# WKUPAON_CM register map
Vendor: Texas Instruments
Peripheral module from a debugger description file (folder omap5430_ES2_PUBLIC).
Registers are 32-bit, access per field, reset 0x30000 unless marked. A register's access mark holds for its fields unless they carry their own. Offsets are as the file gives them; lines under a group give offsets from that group; [hi:lo] are bit positions; {n}, {i} and the like mark numbered series; 'fields as' and 'values as' point back to an identical list; <NAME> marks a mode.

## WKUPAON_CM
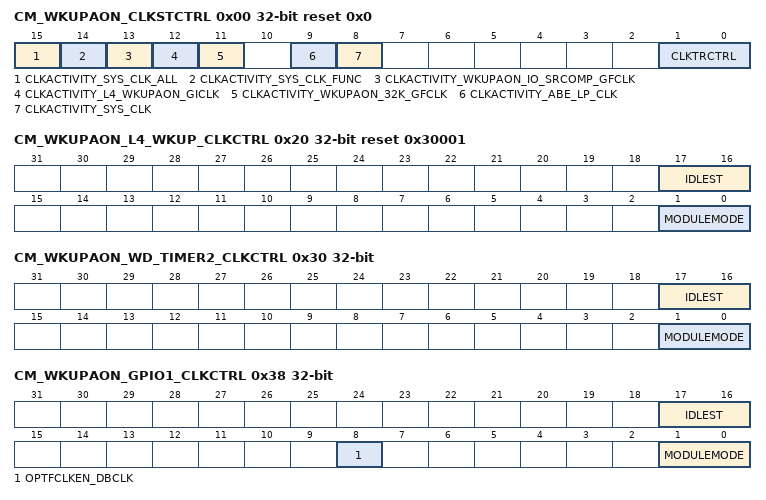
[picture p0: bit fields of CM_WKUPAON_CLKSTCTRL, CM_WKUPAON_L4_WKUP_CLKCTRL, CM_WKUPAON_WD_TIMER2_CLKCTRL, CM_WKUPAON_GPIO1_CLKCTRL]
0x00 CM_WKUPAON_CLKSTCTRL reset 0x0 — This register enables the domain power state transition. It controls the HW supervised domain power state transition between ON-ACTIVE and ON-INACTIVE states. It also holds 1 status bit per clock input of the domain.
  [15] CLKACTIVITY_SYS_CLK_ALL ro — This field indicates the state of the SYS_CLK runing at SCRM level because of any SCRM clock request. [warm reset insensitive]
    0=Corresponding_clock_is_definitely_gated; 1=CLKACTIVITY_SYS_CLK_ALL_1_r (Corresponding clock is running or gating/ungating transition is on-going)
  [14] CLKACTIVITY_SYS_CLK_FUNC ro — This field indicates the state of the functional SYS_CLK clocks in the domain (this exclude activity of EMU_SYS_GCLK clock). [warm reset insensitive]
    0=Corresponding_clock_is_definitely_gated; 1=CLKACTIVITY_SYS_CLK_FUNC_1_r (Corresponding clock is running or gating/ungating transition is on-going)
  [13] CLKACTIVITY_WKUPAON_IO_SRCOMP_GFCLK ro — This field indicates the state of the WKUPAON_IO_SRCOMP_GFCLK clock in the domain. [warm reset insensitive]
    0=Inact (Corresponding clock is definitely gated); 1=Act (Corresponding clock is running or gating/ungating transition is on-going)
  [12] CLKACTIVITY_L4_WKUPAON_GICLK ro — This field indicates the state of the WKUPAON_GICLK clock in the domain. [warm reset insensitive]
    0=Corresponding_clock_is_definitely_gated; 1=CLKACTIVITY_L4_WKUPAON_GICLK_1_r (Corresponding clock is running or gating/ungating transition is on-going)
  [11] CLKACTIVITY_WKUPAON_32K_GFCLK ro — This field indicates the state of the WKUPAON_32K_GFCLK clock in the domain. [warm reset insensitive]
    values as CLKACTIVITY_WKUPAON_IO_SRCOMP_GFCLK
  [9] CLKACTIVITY_ABE_LP_CLK ro — This field indicates the state of the ABE_LP_CLK clock in the domain. [warm reset insensitive]
    values as CLKACTIVITY_WKUPAON_IO_SRCOMP_GFCLK
  [8] CLKACTIVITY_SYS_CLK ro — This field indicates the state of the SYS_CLK clock in the domain (it includes profiling, EMU_SYS_GCLK and all functional SYS_CLK). [warm reset insensitive]
    values as CLKACTIVITY_WKUPAON_IO_SRCOMP_GFCLK
  [1:0] CLKTRCTRL rw — Controls the clock state transition of the WKUPAON clock domain.
    0=NO_SLEEP (NO_SLEEP: Sleep transition cannot be initiated. Wakeup transition may however occur.); 2=SW_WKUP (SW_WKUP: Start a software forced wake-up transition on the domain.); 3=HW_AUTO (HW_AUTO: Automatic transition is enabled. Sleep and wakeup transition are based upon hardware conditions.)
0x20 CM_WKUPAON_L4_WKUP_CLKCTRL ro reset 0x30001 — This register manages the WKUPAON clocks.
  [17:16] IDLEST — Module idle status. [warm reset insensitive]
    0=Func (Module is fully functional, including INTRCONN); 1=Trans (Module is performing transition: wakeup, or sleep, or sleep abortion); 2=Idle (Module is in Idle mode (only INTRCONN part). It is functional if using separate functional clock); 3=Disable (Module is disabled and cannot be accessed)
  [1:0] MODULEMODE — Control the way mandatory clocks are managed.
    1=AUTO (Module is managed automatically by HW according to clock domain transition. A clock domain sleep transition put module into idle. A wakeup domain transition put it back into function. If[1:0] CLKTRCTRL = 0x3 (HW_AUTO), any INTRCONN access to module is always granted. Module clocks may be gated according to the clock domain state.)
0x30 CM_WKUPAON_WD_TIMER2_CLKCTRL — This register manages the WD_TIMER2 clocks.
  [17:16] IDLEST ro — Module idle status. [warm reset insensitive]
    values as CM_WKUPAON_L4_WKUP_CLKCTRL.IDLEST
  [1:0] MODULEMODE rw — Control the way mandatory clocks are managed.
    0=DISABLED (Module is disable by SW. Any INTRCONN access to module results in an error, except if resulting from a module wakeup (asynchronous wakeup).); 2=ENABLE (Module is explicitly enabled. Interface clock (if not used for functions) may be gated according to the clock domain state. Functional clocks are guarantied to stay present. As long as in this configuration, power domain sleep transition cannot happen.)
0x38 CM_WKUPAON_GPIO1_CLKCTRL — This register manages the GPIO1 clocks.
  [17:16] IDLEST ro — Module idle status. [warm reset insensitive]
    values as CM_WKUPAON_L4_WKUP_CLKCTRL.IDLEST
  [8] OPTFCLKEN_DBCLK rw — Optional functional clock control.
    0=FCLK_DIS (Optional functional clock is disabled); 1=FCLK_EN (Optional functional clock is enabled)
  [1:0] MODULEMODE rw — Control the way mandatory clocks are managed.
    0=DISABLED (Module is disable by SW. Any INTRCONN access to module results in an error, except if resulting from a module wakeup (asynchronous wakeup).); 1=RESERVED (Module is managed automatically by HW according to clock domain transition. A clock domain sleep transition put module into idle. A wakeup domain transition put it back into function. If[1:0] CLKTRCTRL = 0x3 (HW_AUTO), any INTRCONN access to module is always granted. Module clocks may be gated according to the clock domain state.)
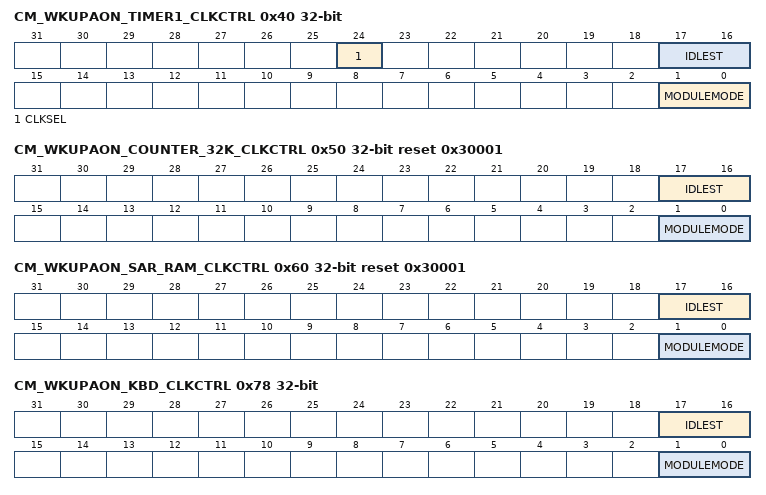
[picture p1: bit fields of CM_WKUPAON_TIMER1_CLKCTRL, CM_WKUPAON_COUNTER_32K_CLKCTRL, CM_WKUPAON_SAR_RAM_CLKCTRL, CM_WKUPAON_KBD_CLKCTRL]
0x40 CM_WKUPAON_TIMER1_CLKCTRL — This register manages the TIMER1 clocks.
  [24] CLKSEL rw — Select the source of the functional clock
    0=SEL_SYS_CLK (Selects the SYS_CLK as the source); 1=SEL_32K_CLK (Selects the 32KHz as the source)
  [17:16] IDLEST ro — Module idle status. [warm reset insensitive]
    values as CM_WKUPAON_L4_WKUP_CLKCTRL.IDLEST
  [1:0] MODULEMODE rw — Control the way mandatory clocks are managed.
    values as CM_WKUPAON_WD_TIMER2_CLKCTRL.MODULEMODE
0x50 CM_WKUPAON_COUNTER_32K_CLKCTRL ro reset 0x30001 — This register manages the COUNTER_32K clocks.
  fields as CM_WKUPAON_L4_WKUP_CLKCTRL
0x60 CM_WKUPAON_SAR_RAM_CLKCTRL ro reset 0x30001 — This register manages the SAR_RAM clocks.
  [17:16] IDLEST — Module idle status. [warm reset insensitive]
    values as CM_WKUPAON_L4_WKUP_CLKCTRL.IDLEST
  [1:0] MODULEMODE — Control the way mandatory clocks are managed.
    1=AUTO (Module is managed automatically by HW according to clock domain transition. A clock domain sleep transition put module into idle. A wakeup domain transition put it back into function. If[1:0]CLKTRCTRL = 0x3 (HW_AUTO), any INTRCONN access to module is always granted. Module clocks may be gated according to the clock domain state.)
0x78 CM_WKUPAON_KBD_CLKCTRL — This register manages the KBD clocks.
  fields as CM_WKUPAON_WD_TIMER2_CLKCTRL
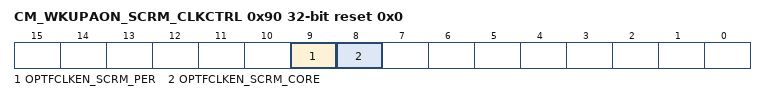
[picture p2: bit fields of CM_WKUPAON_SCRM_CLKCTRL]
0x90 CM_WKUPAON_SCRM_CLKCTRL reset 0x0 — This register manages the SCRM clocks.
  [9] OPTFCLKEN_SCRM_PER rw — Optional functional clock control. 0x0: Optional functional clock is disabled 0x1: Optional functional clock is enabled
  [8] OPTFCLKEN_SCRM_CORE rw — Optional functional clock control.
    values as CM_WKUPAON_GPIO1_CLKCTRL.OPTFCLKEN_DBCLK
0x98 CM_WKUPAON_IO_SRCOMP_CLKCTRL reset 0x0 — This register manages the clock delivered to the IO Slew rate compensation cells. [warm reset insensitive]
  [8] CLKEN_SRCOMP_FCLK rw — Functional clock control.
    0=FCLK_DIS (Functional clock is disabled); 1=FCLK_EN (Functional clock is enabled.)
